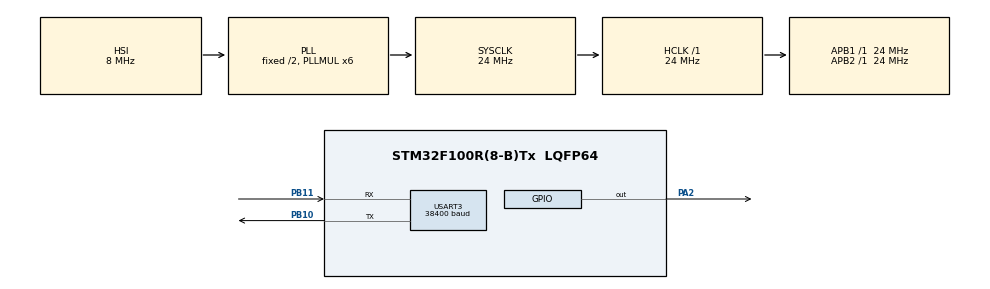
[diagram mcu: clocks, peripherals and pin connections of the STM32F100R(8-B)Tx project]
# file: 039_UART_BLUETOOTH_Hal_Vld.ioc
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Mcu.Family=STM32F1
Mcu.Name=STM32F100R(8-B)Tx
Mcu.Package=LQFP64
NVIC.PriorityGroup=NVIC_PRIORITYGROUP_4
PA13.Mode=Serial_Wire
PA13.Signal=SYS_JTMS-SWDIO
PA14.Mode=Serial_Wire
PA14.Signal=SYS_JTCK-SWCLK
PA2.Signal=GPIO_Output
PB10.Mode=Asynchronous
PB10.Signal=USART3_TX
PB11.Mode=Asynchronous
PB11.Signal=USART3_RX
ProjectManager.HeapSize=0x200
ProjectManager.StackSize=0x400
ProjectManager.TargetToolchain=STM32CubeIDE
RCC.AHBFreq_Value=24000000
RCC.APB1Freq_Value=24000000
RCC.APB1TimFreq_Value=24000000
RCC.APB2Freq_Value=24000000
RCC.APB2TimFreq_Value=24000000
RCC.HCLKFreq_Value=24000000
RCC.PLLMUL=RCC_PLL_MUL6
RCC.SYSCLKFreq_VALUE=24000000
RCC.SYSCLKSource=RCC_SYSCLKSOURCE_PLLCLK
USART3.BaudRate=38400
USART3.VirtualMode=VM_ASYNC
board=custom

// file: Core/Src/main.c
/* USER CODE BEGIN Header */
/**
  ******************************************************************************
  * @file           : main.c
  * @brief          : Main program body
  ******************************************************************************
  * @attention
  *
  * Copyright (c) 2024 STMicroelectronics.
  * All rights reserved.
  *
  * This software is licensed under terms that can be found in the LICENSE file
  * in the root directory of this software component.
  * If no LICENSE file comes with this software, it is provided AS-IS.
  *
  ******************************************************************************
  */
/* USER CODE END Header */
#include "main.h"

/* USER CODE BEGIN Includes */
#include <stdbool.h>
#include <string.h>

/* USER CODE END Includes */

UART_HandleTypeDef huart3;

/* USER CODE BEGIN PV */
char tx_buff[20];
char rx_buff[20];
bool led_state = false;

/* USER CODE END PV */

void SystemClock_Config(void);
static void MX_GPIO_Init(void);
static void MX_USART3_UART_Init(void);

int main(void)
{

  /* MCU Configuration--------------------------------------------------------*/

  /* Reset of all peripherals, Initializes the Flash interface and the Systick. */
  HAL_Init();

  /* Configure the system clock */
  SystemClock_Config();

  /* Initialize all configured peripherals */
  MX_GPIO_Init();
  MX_USART3_UART_Init();

  /* Infinite loop */
  while (1)
  {

    /* USER CODE BEGIN 3 */
	  HAL_UART_Transmit(&huart3, (uint8_t*) tx_buff, sprintf(tx_buff,"AT"), 100);

	  HAL_UART_Receive(&huart3,(uint8_t*)rx_buff, 20,1000);

	 if(rx_buff[0] == 'l' ){
		 HAL_GPIO_WritePin(GPIOA, GPIO_PIN_2, GPIO_PIN_SET);
		 if(led_state != true){
			 HAL_UART_Transmit(&huart3, (uint8_t *)tx_buff, sprintf(tx_buff,"LIGHTS ON"), 100);
		 }
		 led_state = true;
	 }
	 else if(rx_buff[0] == 'o' ){
		 HAL_GPIO_WritePin(GPIOA, GPIO_PIN_2, GPIO_PIN_RESET);
	 	 if(led_state != false){
	 		 HAL_UART_Transmit(&huart3, (uint8_t *)tx_buff, sprintf(tx_buff,"LIGHTS OFF"), 100);
	 	 }
	 	 led_state = false;
  	 }
  }

  /* USER CODE END 3 */
}

void SystemClock_Config(void)
{
  RCC_OscInitTypeDef RCC_OscInitStruct = {0};
  RCC_ClkInitTypeDef RCC_ClkInitStruct = {0};

  /** Initializes the RCC Oscillators according to the specified parameters
  * in the RCC_OscInitTypeDef structure.
  */
  RCC_OscInitStruct.OscillatorType = RCC_OSCILLATORTYPE_HSI;
  RCC_OscInitStruct.HSIState = RCC_HSI_ON;
  RCC_OscInitStruct.HSICalibrationValue = RCC_HSICALIBRATION_DEFAULT;
  RCC_OscInitStruct.PLL.PLLState = RCC_PLL_ON;
  RCC_OscInitStruct.PLL.PLLSource = RCC_PLLSOURCE_HSI_DIV2;
  RCC_OscInitStruct.PLL.PLLMUL = RCC_PLL_MUL6;
  if (HAL_RCC_OscConfig(&RCC_OscInitStruct) != HAL_OK)
  {
    Error_Handler();
  }

  /** Initializes the CPU, AHB and APB buses clocks
  */
  RCC_ClkInitStruct.ClockType = RCC_CLOCKTYPE_HCLK|RCC_CLOCKTYPE_SYSCLK
                              |RCC_CLOCKTYPE_PCLK1|RCC_CLOCKTYPE_PCLK2;
  RCC_ClkInitStruct.SYSCLKSource = RCC_SYSCLKSOURCE_PLLCLK;
  RCC_ClkInitStruct.AHBCLKDivider = RCC_SYSCLK_DIV1;
  RCC_ClkInitStruct.APB1CLKDivider = RCC_HCLK_DIV1;
  RCC_ClkInitStruct.APB2CLKDivider = RCC_HCLK_DIV1;

  if (HAL_RCC_ClockConfig(&RCC_ClkInitStruct, FLASH_LATENCY_0) != HAL_OK)
  {
    Error_Handler();
  }
}

static void MX_USART3_UART_Init(void)
{

  huart3.Instance = USART3;
  huart3.Init.BaudRate = 38400;
  huart3.Init.WordLength = UART_WORDLENGTH_8B;
  huart3.Init.StopBits = UART_STOPBITS_1;
  huart3.Init.Parity = UART_PARITY_NONE;
  huart3.Init.Mode = UART_MODE_TX_RX;
  huart3.Init.HwFlowCtl = UART_HWCONTROL_NONE;
  huart3.Init.OverSampling = UART_OVERSAMPLING_16;
  if (HAL_UART_Init(&huart3) != HAL_OK)
  {
    Error_Handler();
  }

}

static void MX_GPIO_Init(void)
{
  GPIO_InitTypeDef GPIO_InitStruct = {0};

  /* GPIO Ports Clock Enable */
  __HAL_RCC_GPIOA_CLK_ENABLE();
  __HAL_RCC_GPIOB_CLK_ENABLE();

  /*Configure GPIO pin Output Level */
  HAL_GPIO_WritePin(GPIOA, GPIO_PIN_2, GPIO_PIN_RESET);

  /*Configure GPIO pin : PA2 */
  GPIO_InitStruct.Pin = GPIO_PIN_2;
  GPIO_InitStruct.Mode = GPIO_MODE_OUTPUT_PP;
  GPIO_InitStruct.Pull = GPIO_NOPULL;
  GPIO_InitStruct.Speed = GPIO_SPEED_FREQ_LOW;
  HAL_GPIO_Init(GPIOA, &GPIO_InitStruct);

}

void Error_Handler(void)
{
  __disable_irq();
  while (1)
  {
  }
}
